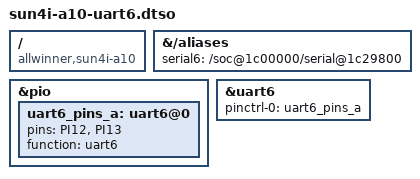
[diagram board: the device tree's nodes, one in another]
/dts-v1/;
/plugin/;

/ {
	compatible = "allwinner,sun4i-a10";

	fragment@0 {
		target-path = "/aliases";
		__overlay__ {
			serial6 = "/soc@1c00000/serial@1c29800";
		};
	};

	fragment@1 {
		target = <&pio>;
		__overlay__ {
			uart6_pins_a: uart6@0 {
				pins = "PI12", "PI13";
				function = "uart6";
			};
		};
	};

	fragment@2 {
		target = <&uart6>;
		 __overlay__ {
			pinctrl-names = "default";
			pinctrl-0 = <&uart6_pins_a>;
			status = "okay";
		};
	};
};
